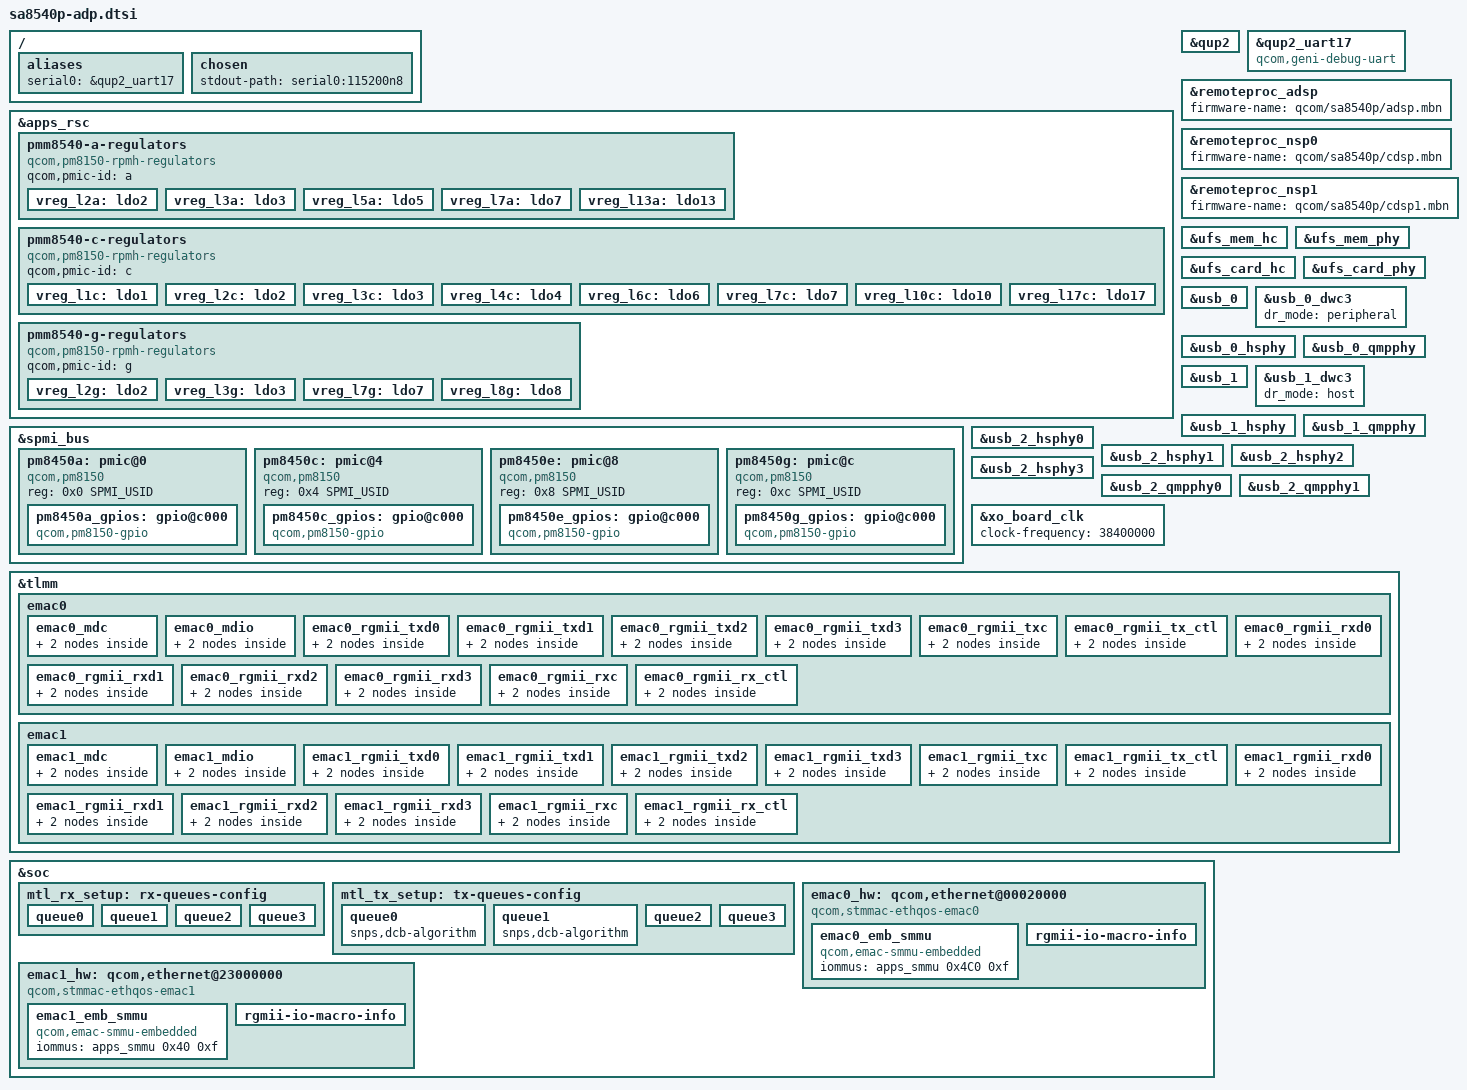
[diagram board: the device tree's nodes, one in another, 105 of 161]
// SPDX-License-Identifier: BSD-3-Clause
/*
 * Copyright (c) 2021, The Linux Foundation. All rights reserved.
 * Copyright (c) 2022, Linaro Limited
 */

#include <dt-bindings/gpio/gpio.h>
#include <dt-bindings/regulator/qcom,rpmh-regulator.h>
#include <dt-bindings/spmi/spmi.h>

#include "sa8540p.dtsi"
#include "pm8150.dtsi"

/ {
	aliases {
		serial0 = &qup2_uart17;
	};

	chosen {
		stdout-path = "serial0:115200n8";
	};
};

&apps_rsc {
	pmm8540-a-regulators {
		compatible = "qcom,pm8150-rpmh-regulators";
		qcom,pmic-id = "a";

		vreg_l2a: ldo2 {
			regulator-name = "vreg_l2a";
			regulator-min-microvolt = <1800000>;
			regulator-max-microvolt = <2700000>;
			regulator-initial-mode = <RPMH_REGULATOR_MODE_HPM>;
			regulator-allow-set-load;
		};

		vreg_l3a: ldo3 {
			regulator-name = "vreg_l3a";
			regulator-min-microvolt = <1200000>;
			regulator-max-microvolt = <1208000>;
			regulator-initial-mode = <RPMH_REGULATOR_MODE_HPM>;
			regulator-allow-set-load;
		};

		vreg_l5a: ldo5 {
			regulator-name = "vreg_l5a";
			regulator-min-microvolt = <912000>;
			regulator-max-microvolt = <912000>;
			regulator-initial-mode = <RPMH_REGULATOR_MODE_HPM>;
			regulator-allow-set-load;
		};

		vreg_l7a: ldo7 {
			regulator-name = "vreg_l7a";
			regulator-min-microvolt = <1800000>;
			regulator-max-microvolt = <1800000>;
			regulator-initial-mode = <RPMH_REGULATOR_MODE_HPM>;
			regulator-allow-set-load;
		};

		vreg_l13a: ldo13 {
			regulator-name = "vreg_l13a";
			regulator-min-microvolt = <3072000>;
			regulator-max-microvolt = <3072000>;
			regulator-initial-mode = <RPMH_REGULATOR_MODE_HPM>;
			regulator-allow-set-load;
		};
	};

	pmm8540-c-regulators {
		compatible = "qcom,pm8150-rpmh-regulators";
		qcom,pmic-id = "c";

		vreg_l1c: ldo1 {
			regulator-name = "vreg_l1c";
			regulator-min-microvolt = <912000>;
			regulator-max-microvolt = <912000>;
			regulator-initial-mode = <RPMH_REGULATOR_MODE_HPM>;
			regulator-allow-set-load;
		};

		vreg_l2c: ldo2 {
			regulator-name = "vreg_l2c";
			regulator-min-microvolt = <3072000>;
			regulator-max-microvolt = <3072000>;
			regulator-initial-mode = <RPMH_REGULATOR_MODE_HPM>;
			regulator-allow-set-load;
		};

		vreg_l3c: ldo3 {
			regulator-name = "vreg_l3c";
			regulator-min-microvolt = <1200000>;
			regulator-max-microvolt = <1200000>;
			regulator-initial-mode = <RPMH_REGULATOR_MODE_HPM>;
			regulator-allow-set-load;
		};

		vreg_l4c: ldo4 {
			regulator-name = "vreg_l4c";
			regulator-min-microvolt = <1200000>;
			regulator-max-microvolt = <1208000>;
			regulator-initial-mode = <RPMH_REGULATOR_MODE_HPM>;
			regulator-allow-set-load;
		};

		vreg_l6c: ldo6 {
			regulator-name = "vreg_l6c";
			regulator-min-microvolt = <1200000>;
			regulator-max-microvolt = <1200000>;
			regulator-initial-mode = <RPMH_REGULATOR_MODE_HPM>;
			regulator-allow-set-load;
		};

		vreg_l7c: ldo7 {
			regulator-name = "vreg_l7c";
			regulator-min-microvolt = <1800000>;
			regulator-max-microvolt = <1800000>;
			regulator-initial-mode = <RPMH_REGULATOR_MODE_HPM>;
			regulator-allow-set-load;
		};

		vreg_l10c: ldo10 {
			regulator-name = "vreg_l10c";
			regulator-min-microvolt = <2504000>;
			regulator-max-microvolt = <2504000>;
			regulator-initial-mode = <RPMH_REGULATOR_MODE_HPM>;
			regulator-allow-set-load;
		};

		vreg_l17c: ldo17 {
			regulator-name = "vreg_l17c";
			regulator-min-microvolt = <2504000>;
			regulator-max-microvolt = <2504000>;
			regulator-initial-mode = <RPMH_REGULATOR_MODE_HPM>;
			regulator-allow-set-load;
		};
	};

	pmm8540-g-regulators {
		compatible = "qcom,pm8150-rpmh-regulators";
		qcom,pmic-id = "g";

		vreg_l2g: ldo2 {
			regulator-name = "vreg_l2g";
			regulator-min-microvolt = <1800000>;
			regulator-max-microvolt = <2700000>;
			regulator-initial-mode = <RPMH_REGULATOR_MODE_HPM>;
			regulator-allow-set-load;
		};

		vreg_l3g: ldo3 {
			regulator-name = "vreg_l3g";
			regulator-min-microvolt = <1200000>;
			regulator-max-microvolt = <1200000>;
			regulator-initial-mode = <RPMH_REGULATOR_MODE_HPM>;
			regulator-allow-set-load;
		};

		vreg_l7g: ldo7 {
			regulator-name = "vreg_l7g";
			regulator-min-microvolt = <1800000>;
			regulator-max-microvolt = <1800000>;
			regulator-initial-mode = <RPMH_REGULATOR_MODE_HPM>;
			regulator-allow-set-load;
		};

		vreg_l8g: ldo8 {
			regulator-name = "vreg_l8g";
			regulator-min-microvolt = <880000>;
			regulator-max-microvolt = <880000>;
			regulator-initial-mode = <RPMH_REGULATOR_MODE_HPM>;
			regulator-allow-set-load;
		};
	};
};

&qup2 {
	status = "okay";
};

&qup2_uart17 {
	compatible = "qcom,geni-debug-uart";
	status = "okay";
};

&remoteproc_adsp {
	firmware-name = "qcom/sa8540p/adsp.mbn";
	status = "okay";
};

&remoteproc_nsp0 {
	firmware-name = "qcom/sa8540p/cdsp.mbn";
	status = "okay";
};

&remoteproc_nsp1 {
	firmware-name = "qcom/sa8540p/cdsp1.mbn";
	status = "okay";
};

&spmi_bus {
	pm8450a: pmic@0 {
		compatible = "qcom,pm8150", "qcom,spmi-pmic";
		reg = <0x0 SPMI_USID>;
		#address-cells = <1>;
		#size-cells = <0>;

		pm8450a_gpios: gpio@c000 {
			compatible = "qcom,pm8150-gpio";
			reg = <0xc000>;
			gpio-controller;
			#gpio-cells = <2>;
			interrupt-controller;
			#interrupt-cells = <2>;
		};
	};

	pm8450c: pmic@4 {
		compatible = "qcom,pm8150", "qcom,spmi-pmic";
		reg = <0x4 SPMI_USID>;
		#address-cells = <1>;
		#size-cells = <0>;

		pm8450c_gpios: gpio@c000 {
			compatible = "qcom,pm8150-gpio";
			reg = <0xc000>;
			gpio-controller;
			#gpio-cells = <2>;
			interrupt-controller;
			#interrupt-cells = <2>;
		};
	};

	pm8450e: pmic@8 {
		compatible = "qcom,pm8150", "qcom,spmi-pmic";
		reg = <0x8 SPMI_USID>;
		#address-cells = <1>;
		#size-cells = <0>;

		pm8450e_gpios: gpio@c000 {
			compatible = "qcom,pm8150-gpio";
			reg = <0xc000>;
			gpio-controller;
			#gpio-cells = <2>;
			interrupt-controller;
			#interrupt-cells = <2>;
		};
	};

	pm8450g: pmic@c {
		compatible = "qcom,pm8150", "qcom,spmi-pmic";
		reg = <0xc SPMI_USID>;
		#address-cells = <1>;
		#size-cells = <0>;

		pm8450g_gpios: gpio@c000 {
			compatible = "qcom,pm8150-gpio";
			reg = <0xc000>;
			gpio-controller;
			#gpio-cells = <2>;
			interrupt-controller;
			#interrupt-cells = <2>;
		};
	};
};

&ufs_mem_hc {
	reset-gpios = <&tlmm 228 GPIO_ACTIVE_LOW>;

	vcc-supply = <&vreg_l17c>;
	vcc-max-microamp = <800000>;
	vccq-supply = <&vreg_l6c>;
	vccq-max-microamp = <900000>;

	status = "okay";
};

&ufs_mem_phy {
	vdda-phy-supply = <&vreg_l8g>;
	vdda-pll-supply = <&vreg_l3g>;

	status = "okay";
};

&ufs_card_hc {
	reset-gpios = <&tlmm 229 GPIO_ACTIVE_LOW>;

	vcc-supply = <&vreg_l10c>;
	vcc-max-microamp = <800000>;
	vccq-supply = <&vreg_l3c>;
	vccq-max-microamp = <900000>;

	status = "okay";
};

&ufs_card_phy {
	vdda-phy-supply = <&vreg_l8g>;
	vdda-pll-supply = <&vreg_l3g>;

	status = "okay";
};

&usb_0 {
	status = "okay";
};

&usb_0_dwc3 {
	/* TODO: Define USB-C connector properly */
	dr_mode = "peripheral";
};

&usb_0_hsphy {
	vdda-pll-supply = <&vreg_l5a>;
	vdda18-supply = <&vreg_l7a>;
	vdda33-supply = <&vreg_l13a>;

	status = "okay";
};

&usb_0_qmpphy {
	vdda-phy-supply = <&vreg_l3a>;
	vdda-pll-supply = <&vreg_l5a>;

	status = "okay";
};

&usb_1 {
	status = "okay";
};

&usb_1_dwc3 {
	/* TODO: Define USB-C connector properly */
	dr_mode = "host";
};

&usb_1_hsphy {
	vdda-pll-supply = <&vreg_l1c>;
	vdda18-supply = <&vreg_l7c>;
	vdda33-supply = <&vreg_l2c>;

	status = "okay";
};

&usb_1_qmpphy {
	vdda-phy-supply = <&vreg_l4c>;
	vdda-pll-supply = <&vreg_l1c>;

	status = "okay";
};

&usb_2_hsphy0 {
	vdda-pll-supply = <&vreg_l5a>;
	vdda18-supply = <&vreg_l7g>;
	vdda33-supply = <&vreg_l13a>;

	status = "okay";
};

&usb_2_hsphy1 {
	vdda-pll-supply = <&vreg_l5a>;
	vdda18-supply = <&vreg_l7g>;
	vdda33-supply = <&vreg_l13a>;

	status = "okay";
};

&usb_2_hsphy2 {
	vdda-pll-supply = <&vreg_l5a>;
	vdda18-supply = <&vreg_l7g>;
	vdda33-supply = <&vreg_l13a>;

	status = "okay";
};

&usb_2_hsphy3 {
	vdda-pll-supply = <&vreg_l5a>;
	vdda18-supply = <&vreg_l7g>;
	vdda33-supply = <&vreg_l13a>;

	status = "okay";
};

&usb_2_qmpphy0 {
	vdda-phy-supply = <&vreg_l3a>;
	vdda-pll-supply = <&vreg_l5a>;

	status = "okay";
};

&usb_2_qmpphy1 {
	vdda-phy-supply = <&vreg_l3a>;
	vdda-pll-supply = <&vreg_l5a>;

	status = "okay";
};

&xo_board_clk {
	clock-frequency = <38400000>;
};

&tlmm {
	emac0 {
		emac0_mdc: emac0_mdc {
			mux {
				pins = "gpio175";
				function = "rgmii_0";
			};

			config {
				pins = "gpio175";
				bias-pull-up;
				drive-strength = <16>;
			};
		};

		emac0_mdio: emac0_mdio {
			mux {
				pins = "gpio176";
				function = "rgmii_0";
			};

			config {
				pins = "gpio176";
				bias-pull-up;
				drive-strength = <16>;
			};
		};

		emac0_rgmii_txd0: emac0_rgmii_txd0 {
			mux {
				pins = "gpio185";
				function = "rgmii_0";
			};

			config {
				pins = "gpio185";
				//output-enable;
				bias-pull-up;
				drive-strength = <16>;
			};
		};

		emac0_rgmii_txd1: emac0_rgmii_txd1 {
			mux {
				pins = "gpio186";
				function = "rgmii_0";
			};

			config {
				pins = "gpio186";
				bias-pull-up;
				drive-strength = <16>;
			};
		};

		emac0_rgmii_txd2: emac0_rgmii_txd2 {
			mux {
				pins = "gpio187";
				function = "rgmii_0";
			};

			config {
				pins = "gpio187";
				bias-pull-up;
				drive-strength = <16>;
			};
		};

		emac0_rgmii_txd3: emac0_rgmii_txd3 {
			mux {
				pins = "gpio188";
				function = "rgmii_0";
			};

			config {
				pins = "gpio188";
				bias-pull-up;
				drive-strength = <16>;
			};
		};

		emac0_rgmii_txc: emac0_rgmii_txc {
			mux {
				pins = "gpio183";
				function = "rgmii_0";
			};

			config {
				pins = "gpio183";
				bias-pull-up;
				drive-strength = <16>;
			};
		};

		emac0_rgmii_tx_ctl: emac0_rgmii_tx_ctl {
			mux {
				pins = "gpio184";
				function = "rgmii_0";
			};

			config {
				pins = "gpio184";
				bias-pull-up;
				drive-strength = <16>;
			};
		};

		emac0_rgmii_rxd0: emac0_rgmii_rxd0 {
			mux {
				pins = "gpio179";
				function = "rgmii_0";
			};

			config {
				pins = "gpio179";
				bias-disable;  /* NO pull */
				drive-strength = <16>;  /* 16MA */
			};
		};

		emac0_rgmii_rxd1: emac0_rgmii_rxd1 {
			mux {
				pins = "gpio180";
				function = "rgmii_0";
			};

			config {
				pins = "gpio180";
				bias-disable;  /* NO pull */
				drive-strength = <16>;
			};
		};

		emac0_rgmii_rxd2: emac0_rgmii_rxd2 {
			mux {
				pins = "gpio181";
				function = "rgmii_0";
			};

			config {
				pins = "gpio181";
				bias-disable;	/* NO pull */
				drive-strength = <16>;
			};
		};

		emac0_rgmii_rxd3: emac0_rgmii_rxd3 {
			mux {
				pins = "gpio182";
				function = "rgmii_0";
			};

			config {
				pins = "gpio182";
				bias-disable;	/* NO pull */
				drive-strength = <16>;
			};
		};

		emac0_rgmii_rxc: emac0_rgmii_rxc {
			mux {
				pins = "gpio177";
				function = "rgmii_0";
			};

			config {
				pins = "gpio177";
				bias-disable;	/* NO pull */
				drive-strength = <16>;
			};
		};

		emac0_rgmii_rx_ctl: emac0_rgmii_rx_ctl {
			mux {
				pins = "gpio178";
				function = "rgmii_0";
			};

			config {
				pins = "gpio178";
				bias-disable;  /* NO pull */
				drive-strength = <16>;
			};
		};
	};

	emac1 {
		emac1_mdc: emac1_mdc {
			mux {
				pins = "gpio97";
				function = "rgmii_1";
			};

			config {
				pins = "gpio97";
				bias-pull-up;
				drive-strength = <16>;
			};
		};

		emac1_mdio: emac1_mdio {
			mux {
				pins = "gpio98";
				function = "rgmii_1";
			};

			config {
				pins = "gpio98";
				bias-pull-up;
				drive-strength = <16>;
			};
		};

		emac1_rgmii_txd0: emac1_rgmii_txd0 {
			mux {
				pins = "gpio107";
				function = "rgmii_1";
			};

			config {
				pins = "gpio107";
				//output-enable;
				bias-pull-up;
				drive-strength = <16>;
			};
		};

		emac1_rgmii_txd1: emac1_rgmii_txd1 {
			mux {
				pins = "gpio108";
				function = "rgmii_1";
			};

			config {
				pins = "gpio108";
				bias-pull-up;
				drive-strength = <16>;
			};
		};

		emac1_rgmii_txd2: emac1_rgmii_txd2 {
			mux {
				pins = "gpio109";
				function = "rgmii_1";
			};

			config {
				pins = "gpio109";
				bias-pull-up;
				drive-strength = <16>;
			};
		};

		emac1_rgmii_txd3: emac1_rgmii_txd3 {
			mux {
				pins = "gpio110";
				function = "rgmii_1";
			};

			config {
				pins = "gpio110";
				bias-pull-up;
				drive-strength = <16>;
			};
		};

		emac1_rgmii_txc: emac1_rgmii_txc {
			mux {
				pins = "gpio105";
				function = "rgmii_1";
			};

			config {
				pins = "gpio105";
				bias-pull-up;
				drive-strength = <16>;
			};
		};

		emac1_rgmii_tx_ctl: emac1_rgmii_tx_ctl {
			mux {
				pins = "gpio106";
				function = "rgmii_1";
			};

			config {
				pins = "gpio106";
				bias-pull-up;
				drive-strength = <16>;
			};
		};

		emac1_rgmii_rxd0: emac1_rgmii_rxd0 {
			mux {
				pins = "gpio101";
				function = "rgmii_1";
			};

			config {
				pins = "gpio101";
				bias-disable;  /* NO pull */
				drive-strength = <16>;  /* 16MA */
			};
		};

		emac1_rgmii_rxd1: emac1_rgmii_rxd1 {
			mux {
				pins = "gpio102";
				function = "rgmii_1";
			};

			config {
				pins = "gpio102";
				bias-disable;  /* NO pull */
				drive-strength = <16>;
			};
		};

		emac1_rgmii_rxd2: emac1_rgmii_rxd2 {
			mux {
				pins = "gpio103";
				function = "rgmii_1";
			};

			config {
				pins = "gpio103";
				bias-disable;	/* NO pull */
				drive-strength = <16>;
			};
		};

		emac1_rgmii_rxd3: emac1_rgmii_rxd3 {
			mux {
				pins = "gpio104";
				function = "rgmii_1";
			};

			config {
				pins = "gpio104";
				bias-disable;	/* NO pull */
				drive-strength = <16>;
			};
		};

		emac1_rgmii_rxc: emac1_rgmii_rxc {
			mux {
				pins = "gpio99";
				function = "rgmii_1";
			};

			config {
				pins = "gpio99";
				bias-disable;	/* NO pull */
				drive-strength = <16>;
			};
		};

		emac1_rgmii_rx_ctl: emac1_rgmii_rx_ctl {
			mux {
				pins = "gpio100";
				function = "rgmii_1";
			};

			config {
				pins = "gpio100";
				bias-disable;  /* NO pull */
				drive-strength = <16>;
			};
		};
	};
};

&soc {
	mtl_rx_setup: rx-queues-config {
		snps,rx-queues-to-use = <1>;
		snps,rx-sched-sp;

		queue0 {
			snps,dcb-algorithm;
			snps,map-to-dma-channel = <0x0>;
			snps,route-up;
			snps,priority = <0x1>;
		};

		queue1 {
			snps,dcb-algorithm;
			snps,map-to-dma-channel = <0x1>;
			snps,route-ptp;
		};

		queue2 {
			snps,avb-algorithm;
			snps,map-to-dma-channel = <0x2>;
			snps,route-avcp;
		};

		queue3 {
			snps,avb-algorithm;
			snps,map-to-dma-channel = <0x3>;
			snps,priority = <0xC>;
		};
	};

	mtl_tx_setup: tx-queues-config {
		snps,tx-queues-to-use = <1>;
		snps,tx-sched-sp;

		queue0 {
			snps,dcb-algorithm;
		};

		queue1 {
			snps,dcb-algorithm;
		};

		queue2 {
			snps,avb-algorithm;
			snps,send_slope = <0x1000>;
			snps,idle_slope = <0x1000>;
			snps,high_credit = <0x3E800>;
			snps,low_credit = <0xFFC18000>;
		};

		queue3 {
			snps,avb-algorithm;
			snps,send_slope = <0x1000>;
			snps,idle_slope = <0x1000>;
			snps,high_credit = <0x3E800>;
			snps,low_credit = <0xFFC18000>;
		};

	};

	emac0_hw: qcom,ethernet@00020000 {
		compatible = "qcom,stmmac-ethqos-emac0";
		emac-core-version = <0x30000000>;
		qcom,arm-smmu;
		reg = <0x0 0x20000 0x0 0x10000>,
			<0x0 0x36000 0x0 0x100>;
		reg-names = "stmmaceth", "rgmii";
		clocks = <&gcc GCC_EMAC0_AXI_CLK>,
			<&gcc GCC_EMAC0_SLV_AHB_CLK>,
			<&gcc GCC_EMAC0_PTP_CLK>,
			<&gcc GCC_EMAC0_RGMII_CLK>;
		clock-names = "stmmaceth", "pclk", "ptp_ref", "rgmii";
		snps,ptp-ref-clk-rate = <250000000>;
		snps,ptp-req-clk-rate = <96000000>;
		interrupts-extended = <&intc 0 946 4>, <&tlmm 127 2>;
		interrupt-names = "macirq","phy-intr";

		snps,tso;
		snps,pbl = <32>;
		rx-fifo-depth = <4096>;
		tx-fifo-depth = <4096>;
		snps,mtl-rx-config = <&mtl_rx_setup>;
		snps,mtl-tx-config = <&mtl_tx_setup>;

		snps,reset-gpios = <&pm8150_gpios 1 GPIO_ACTIVE_HIGH>;
		vreg_rgmii-supply = <&vreg_l2a>;
		power-domains = <&gcc EMAC_0_GDSC>;
		qcom,phy-intr-redirect = <&tlmm 127 GPIO_ACTIVE_LOW>;
		pinctrl-names = "dev-emac-mdc",
			"dev-emac-mdio",
			"dev-emac-rgmii_txd0_state",
			"dev-emac-rgmii_txd1_state",
			"dev-emac-rgmii_txd2_state",
			"dev-emac-rgmii_txd3_state",
			"dev-emac-rgmii_txc_state",
			"dev-emac-rgmii_tx_ctl_state",
			"dev-emac-rgmii_rxd0_state",
			"dev-emac-rgmii_rxd1_state",
			"dev-emac-rgmii_rxd2_state",
			"dev-emac-rgmii_rxd3_state",
			"dev-emac-rgmii_rxc_state",
			"dev-emac-rgmii_rx_ctl_state";

		pinctrl-0 = <&emac0_mdc>;
		pinctrl-1 = <&emac0_mdio>;

		pinctrl-2 = <&emac0_rgmii_txd0>;
		pinctrl-3 = <&emac0_rgmii_txd1>;
		pinctrl-4 = <&emac0_rgmii_txd2>;
		pinctrl-5 = <&emac0_rgmii_txd3>;
		pinctrl-6 = <&emac0_rgmii_txc>;
		pinctrl-7 = <&emac0_rgmii_tx_ctl>;

		pinctrl-8 = <&emac0_rgmii_rxd0>;
		pinctrl-9 = <&emac0_rgmii_rxd1>;
		pinctrl-10 = <&emac0_rgmii_rxd2>;
		pinctrl-11 = <&emac0_rgmii_rxd3>;
		pinctrl-12 = <&emac0_rgmii_rxc>;
		pinctrl-13 = <&emac0_rgmii_rx_ctl>;

		snps,reset-delays-us = <0 11000 70000>;
		phy-mode = "rgmii";
		phy-fixed-link;

		emac0_emb_smmu: emac0_emb_smmu {
			compatible = "qcom,emac-smmu-embedded";
			iommus = <&apps_smmu 0x4C0 0xf>;
		};

		rgmii-io-macro-info {
			prg-rclk-dly = <904>;
			config-cdr-en = <1>;
			mclk-gating-en = <1>;
			cdr-fine-phase = <1>;
			skip-calc-traffic = <1>;
			data-divide-clk-sel = <0>;
			loopback-en = <0>;
			rx-prog-swap = <1>;
			tx-clk-phase-shift-en = <0>;
			dll-clock-dis = <0>;
			mclk-freq-calc = <0x28>;
			ddr-traffic-init-sel = <0>;
			ddr-traffic-init-sw = <0>;
			ddr-cal-en = <1>;
			tcx0-cycles-dly-line = <64>;
			tcx0-cycles-cnt = <4>;
			test-ctl = <0xC1800000>;
			usr-ctl = <0x2C010800>;
			l3-master-dev = <1>;
			ipv6-wq = <0>;
		};
	};

	emac1_hw: qcom,ethernet@23000000 {
		compatible = "qcom,stmmac-ethqos-emac1";
		emac-core-version = <0x30000000>;
		qcom,arm-smmu;
		reg = <0x0 0x23000000 0x0 0x10000>,
			<0x0 0x23016000 0x0 0x100>;
		reg-names = "stmmaceth", "rgmii";
		clocks = <&gcc GCC_EMAC1_AXI_CLK>,
			<&gcc GCC_EMAC1_SLV_AHB_CLK>,
			<&gcc GCC_EMAC1_PTP_CLK>,
			<&gcc GCC_EMAC1_RGMII_CLK>;
		clock-names = "stmmaceth", "pclk", "ptp_ref", "rgmii";
		snps,ptp-ref-clk-rate = <250000000>;
		snps,ptp-req-clk-rate = <96000000>;
		interrupts-extended = <&intc 0 929 4>, <&tlmm 54 2>;

		interrupt-names = "macirq","phy-intr";

		snps,tso;
		snps,pbl = <32>;
		rx-fifo-depth = <4096>;
		tx-fifo-depth = <4096>;
		snps,mtl-rx-config = <&mtl_rx_setup>;
		snps,mtl-tx-config = <&mtl_tx_setup>;

		snps,reset-gpios = <&pm8150_gpios 2 GPIO_ACTIVE_HIGH>;
		vreg_rgmii-supply = <&vreg_l2g>;
		power-domains = <&gcc EMAC_1_GDSC>;
		qcom,phy-intr-redirect = <&tlmm 54 GPIO_ACTIVE_LOW>;
		pinctrl-names = "dev-emac-mdc",
			"dev-emac-mdio",
			"dev-emac-rgmii_txd0_state",
			"dev-emac-rgmii_txd1_state",
			"dev-emac-rgmii_txd2_state",
			"dev-emac-rgmii_txd3_state",
			"dev-emac-rgmii_txc_state",
			"dev-emac-rgmii_tx_ctl_state",
			"dev-emac-rgmii_rxd0_state",
			"dev-emac-rgmii_rxd1_state",
			"dev-emac-rgmii_rxd2_state",
			"dev-emac-rgmii_rxd3_state",
			"dev-emac-rgmii_rxc_state",
			"dev-emac-rgmii_rx_ctl_state";

		pinctrl-0 = <&emac1_mdc>;
		pinctrl-1 = <&emac1_mdio>;

		pinctrl-2 = <&emac1_rgmii_txd0>;
		pinctrl-3 = <&emac1_rgmii_txd1>;
		pinctrl-4 = <&emac1_rgmii_txd2>;
		pinctrl-5 = <&emac1_rgmii_txd3>;
		pinctrl-6 = <&emac1_rgmii_txc>;
		pinctrl-7 = <&emac1_rgmii_tx_ctl>;

		pinctrl-8 = <&emac1_rgmii_rxd0>;
		pinctrl-9 = <&emac1_rgmii_rxd1>;
		pinctrl-10 = <&emac1_rgmii_rxd2>;
		pinctrl-11 = <&emac1_rgmii_rxd3>;
		pinctrl-12 = <&emac1_rgmii_rxc>;
		pinctrl-13 = <&emac1_rgmii_rx_ctl>;

		snps,reset-delays-us = <0 11000 70000>;
		phy-mode = "rgmii";
		mac2mac;
		mac2mac-rgmii-speed = <1000>;

		emac1_emb_smmu: emac1_emb_smmu {
			compatible = "qcom,emac-smmu-embedded";
			iommus = <&apps_smmu 0x40 0xf>;
		};

		rgmii-io-macro-info {
			prg-rclk-dly = <904>;
			config-cdr-en = <1>;
			mclk-gating-en = <1>;
			cdr-fine-phase = <1>;
			skip-calc-traffic = <1>;
			data-divide-clk-sel = <0>;
			loopback-en = <0>;
			rx-prog-swap = <1>;
			tx-clk-phase-shift-en = <0>;
			dll-clock-dis = <0>;
			mclk-freq-calc = <0x28>;
			ddr-traffic-init-sel = <0>;
			ddr-traffic-init-sw = <0>;
			ddr-cal-en = <1>;
			tcx0-cycles-dly-line = <64>;
			tcx0-cycles-cnt = <4>;
			test-ctl = <0xC1800000>;
			usr-ctl = <0x2C010800>;
			l3-master-dev = <1>;
			ipv6-wq = <0>;
		};
	};
};
/* PINCTRL */
